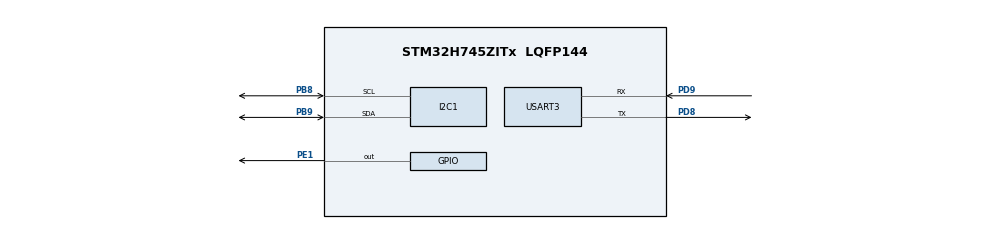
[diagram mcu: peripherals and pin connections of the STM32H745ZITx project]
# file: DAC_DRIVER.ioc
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CortexM4.IPs=FATFS_M4\:I,FREERTOS_M4\:I,IWDG2\:I,RCC,WWDG2\:I,DMA,BDMA,MDMA,NVIC2\:I,ETH,DEBUG,USB_DEVICE_M4\:I,USB_HOST_M4\:I,PDM2PCM_M4\:I,PWR,RESMGR_UTILITY,SYS_M4\:I,CORTEX_M4\:I,OPENAMP_M4\:I,VREFBUF,GPIO
CortexM7.IPs=FATFS_M7\:I,FREERTOS_M7\:I,IWDG1\:I,RCC\:I,WWDG1\:I,DMA\:I,BDMA\:I,MDMA\:I,NVIC1\:I,SYS\:I,ETH\:I,CORTEX_M7\:I,DEBUG\:I,USB_DEVICE_M7\:I,USB_HOST_M7\:I,PDM2PCM_M7\:I,PWR\:I,RESMGR_UTILITY\:I,OPENAMP_M7\:I,VREFBUF\:I,GPIO\:I,I2C1\:I,USART3\:I
CortexM7.Pins=PE1
I2C1.Analog_Filter=I2C_ANALOGFILTER_ENABLE
I2C1.Timing=0x00404C74
Mcu.Family=STM32H7
Mcu.Name=STM32H745ZITx
Mcu.Package=LQFP144
NVIC1.PriorityGroup=NVIC_PRIORITYGROUP_4
NVIC2.PriorityGroup=NVIC_PRIORITYGROUP_4
PB8.Mode=I2C
PB8.PinAttribute=CortexM7
PB8.Signal=I2C1_SCL
PB9.Mode=I2C
PB9.PinAttribute=CortexM7
PB9.Signal=I2C1_SDA
PD8.Mode=Asynchronous
PD8.PinAttribute=CortexM7
PD8.Signal=USART3_TX
PD9.Mode=Asynchronous
PD9.PinAttribute=CortexM7
PD9.Signal=USART3_RX
PE1.PinAttribute=CortexM7
PE1.Signal=GPIO_Output
ProjectManager.HeapSize=M4-0x200,M7-0x200
ProjectManager.StackSize=M4-0x400,M7-0x400
ProjectManager.TargetToolchain=STM32CubeIDE
RCC.ADCFreq_Value=129000000
RCC.APB1Freq_Value=20000000
RCC.APB2Freq_Value=20000000
RCC.APB3Freq_Value=20000000
RCC.APB4Freq_Value=20000000
RCC.CortexFreq_Value=80000000
RCC.D1PPRE=RCC_APB3_DIV2
RCC.D2PPRE1=RCC_APB1_DIV2
RCC.D2PPRE2=RCC_APB2_DIV2
RCC.D3PPRE=RCC_APB4_DIV2
RCC.DIVM1=4
RCC.DIVM3=1
RCC.DIVN1=10
RCC.DIVN3=24
RCC.DIVQ3=4
RCC.HCLKFreq_Value=40000000
RCC.HPRE=RCC_HCLK_DIV2
RCC.HSE_VALUE=8000000
RCC.PLL2FRACN=0
RCC.PLL3FRACN=0
RCC.PLLFRACN=0
RCC.SYSCLKFreq_VALUE=80000000
RCC.SYSCLKSource=RCC_SYSCLKSOURCE_PLLCLK
RCC.SupplySource=PWR_DIRECT_SMPS_SUPPLY
RCC.USBCLockSelection=RCC_USBCLKSOURCE_PLL3
RCC.USBFreq_Value=384000000
USART3.VirtualMode-Asynchronous=VM_ASYNC
VP_SYS_M4_VS_Systick.Mode=SysTick
board=NUCLEO-H745ZI-Q

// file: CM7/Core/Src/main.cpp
/* USER CODE BEGIN Header */
/**
  ******************************************************************************
  * @file           : main.c
  * @brief          : Main program body
  ******************************************************************************
  * @attention
  *
  * Copyright (c) 2022 STMicroelectronics.
  * All rights reserved.
  *
  * This software is licensed under terms that can be found in the LICENSE file
  * in the root directory of this software component.
  * If no LICENSE file comes with this software, it is provided AS-IS.
  *
  ******************************************************************************
  */
/* USER CODE END Header */
#include "main.h"

/* USER CODE BEGIN Includes */
#include <stdio.h>
#include "mcp4716_constants.hpp"  // Constants DAC IC
#include "bsp.hpp"
#include "IDriver.hpp"      // Parent Class
#include "Mcp4716Dac.hpp"  // Inherit class functions

/* USER CODE END Includes */

/* USER CODE BEGIN PD */

#ifndef HSEM_ID_0
#define HSEM_ID_0 (0U) /* HW semaphore 0*/
#endif
/* USER CODE END PD */

I2C_HandleTypeDef hi2c1;

UART_HandleTypeDef huart3;

void SystemClock_Config(void);
static void MX_GPIO_Init(void);
static void MX_I2C1_Init(void);
static void MX_USART3_UART_Init(void);

int main(void)
{
/* USER CODE BEGIN Boot_Mode_Sequence_0 */
  int32_t timeout;
/* USER CODE END Boot_Mode_Sequence_0 */

/* USER CODE BEGIN Boot_Mode_Sequence_1 */
  /* Wait until CPU2 boots and enters in stop mode or timeout*/
//  timeout = 0xFFFF;
//  while((__HAL_RCC_GET_FLAG(RCC_FLAG_D2CKRDY) != RESET) && (timeout-- > 0));
//  if ( timeout < 0 )
//  {
//  Error_Handler();
//  }
/* USER CODE END Boot_Mode_Sequence_1 */
  /* MCU Configuration--------------------------------------------------------*/

  /* Reset of all peripherals, Initializes the Flash interface and the Systick. */
  HAL_Init();

  /* Configure the system clock */
  SystemClock_Config();
/* USER CODE BEGIN Boot_Mode_Sequence_2 */
/* When system initialization is finished, Cortex-M7 will release Cortex-M4 by means of
HSEM notification */
/*HW semaphore Clock enable*/
__HAL_RCC_HSEM_CLK_ENABLE();
/*Take HSEM */
HAL_HSEM_FastTake(HSEM_ID_0);
/*Release HSEM in order to notify the CPU2(CM4)*/
HAL_HSEM_Release(HSEM_ID_0,0);
/* wait until CPU2 wakes up from stop mode */
timeout = 0xFFFF;
while((__HAL_RCC_GET_FLAG(RCC_FLAG_D2CKRDY) == RESET) && (timeout-- > 0));
if ( timeout < 0 )
{
Error_Handler();
}
/* USER CODE END Boot_Mode_Sequence_2 */

  /* Initialize all configured peripherals */
  MX_GPIO_Init();
  MX_I2C1_Init();
  MX_USART3_UART_Init();
  /* USER CODE BEGIN 2 */

  Mcp4716Dac mcp4716dac ;  //  Creating an Object
 //  ddriver -> toggleLed();
 //  mcp4716dac.Init();
 //  mcp4716dac.Write();
 //  mcp4716dac.Init();
 //    mcp4716dac.Write();
 //  mcp4716dac.Read();
 //  mcp4716dac.DeInit();
   //ddriver.DacVoltage(float vref,uint16_t dacvalue,float *voltage);

  /* USER CODE END 2 */

  /* Infinite loop */
  /* USER CODE BEGIN WHILE */
  while (1)
  {
      mcp4716dac.Init();
             mcp4716dac.Write();
             // mcp4716dac.Read();
              mcp4716dac.SerialData();

             mcp4716dac.toggleLed();

             mcp4716dac.GenerateVoltage(1020);

       //    HAL_GPIO_TogglePin(GPIOE,GPIO_PIN_1);
       //    HAL_Delay(500);
             HAL_GPIO_TogglePin(GPIOB,GPIO_PIN_0);
                 HAL_Delay(250);
    /* USER CODE END WHILE */

  }
}

void SystemClock_Config(void)
{
  RCC_OscInitTypeDef RCC_OscInitStruct = {0};
  RCC_ClkInitTypeDef RCC_ClkInitStruct = {0};

  /** Supply configuration update enable
  */
  HAL_PWREx_ConfigSupply(PWR_DIRECT_SMPS_SUPPLY);

  /** Configure the main internal regulator output voltage
  */
  __HAL_PWR_VOLTAGESCALING_CONFIG(PWR_REGULATOR_VOLTAGE_SCALE3);

  while(!__HAL_PWR_GET_FLAG(PWR_FLAG_VOSRDY)) {}

  /** Initializes the RCC Oscillators according to the specified parameters
  * in the RCC_OscInitTypeDef structure.
  */
  RCC_OscInitStruct.OscillatorType = RCC_OSCILLATORTYPE_HSI;
  RCC_OscInitStruct.HSIState = RCC_HSI_DIV1;
  RCC_OscInitStruct.HSICalibrationValue = RCC_HSICALIBRATION_DEFAULT;
  RCC_OscInitStruct.PLL.PLLState = RCC_PLL_ON;
  RCC_OscInitStruct.PLL.PLLSource = RCC_PLLSOURCE_HSI;
  RCC_OscInitStruct.PLL.PLLM = 4;
  RCC_OscInitStruct.PLL.PLLN = 10;
  RCC_OscInitStruct.PLL.PLLP = 2;
  RCC_OscInitStruct.PLL.PLLQ = 2;
  RCC_OscInitStruct.PLL.PLLR = 2;
  RCC_OscInitStruct.PLL.PLLRGE = RCC_PLL1VCIRANGE_3;
  RCC_OscInitStruct.PLL.PLLVCOSEL = RCC_PLL1VCOMEDIUM;
  RCC_OscInitStruct.PLL.PLLFRACN = 0;
  if (HAL_RCC_OscConfig(&RCC_OscInitStruct) != HAL_OK)
  {
    Error_Handler();
  }

  /** Initializes the CPU, AHB and APB buses clocks
  */
  RCC_ClkInitStruct.ClockType = RCC_CLOCKTYPE_HCLK|RCC_CLOCKTYPE_SYSCLK
                              |RCC_CLOCKTYPE_PCLK1|RCC_CLOCKTYPE_PCLK2
                              |RCC_CLOCKTYPE_D3PCLK1|RCC_CLOCKTYPE_D1PCLK1;
  RCC_ClkInitStruct.SYSCLKSource = RCC_SYSCLKSOURCE_PLLCLK;
  RCC_ClkInitStruct.SYSCLKDivider = RCC_SYSCLK_DIV1;
  RCC_ClkInitStruct.AHBCLKDivider = RCC_HCLK_DIV2;
  RCC_ClkInitStruct.APB3CLKDivider = RCC_APB3_DIV2;
  RCC_ClkInitStruct.APB1CLKDivider = RCC_APB1_DIV2;
  RCC_ClkInitStruct.APB2CLKDivider = RCC_APB2_DIV2;
  RCC_ClkInitStruct.APB4CLKDivider = RCC_APB4_DIV2;

  if (HAL_RCC_ClockConfig(&RCC_ClkInitStruct, FLASH_LATENCY_0) != HAL_OK)
  {
    Error_Handler();
  }
}

static void MX_I2C1_Init(void)
{

  hi2c1.Instance = I2C1;
  hi2c1.Init.Timing = 0x00404C74;
  hi2c1.Init.OwnAddress1 = 0;
  hi2c1.Init.AddressingMode = I2C_ADDRESSINGMODE_7BIT;
  hi2c1.Init.DualAddressMode = I2C_DUALADDRESS_DISABLE;
  hi2c1.Init.OwnAddress2 = 0;
  hi2c1.Init.OwnAddress2Masks = I2C_OA2_NOMASK;
  hi2c1.Init.GeneralCallMode = I2C_GENERALCALL_DISABLE;
  hi2c1.Init.NoStretchMode = I2C_NOSTRETCH_DISABLE;
  if (HAL_I2C_Init(&hi2c1) != HAL_OK)
  {
    Error_Handler();
  }

  /** Configure Analogue filter
  */
  if (HAL_I2CEx_ConfigAnalogFilter(&hi2c1, I2C_ANALOGFILTER_ENABLE) != HAL_OK)
  {
    Error_Handler();
  }

  /** Configure Digital filter
  */
  if (HAL_I2CEx_ConfigDigitalFilter(&hi2c1, 0) != HAL_OK)
  {
    Error_Handler();
  }

}

static void MX_USART3_UART_Init(void)
{

  huart3.Instance = USART3;
  huart3.Init.BaudRate = 115200;
  huart3.Init.WordLength = UART_WORDLENGTH_8B;
  huart3.Init.StopBits = UART_STOPBITS_1;
  huart3.Init.Parity = UART_PARITY_NONE;
  huart3.Init.Mode = UART_MODE_TX_RX;
  huart3.Init.HwFlowCtl = UART_HWCONTROL_NONE;
  huart3.Init.OverSampling = UART_OVERSAMPLING_16;
  huart3.Init.OneBitSampling = UART_ONE_BIT_SAMPLE_DISABLE;
  huart3.Init.ClockPrescaler = UART_PRESCALER_DIV1;
  huart3.AdvancedInit.AdvFeatureInit = UART_ADVFEATURE_NO_INIT;
  if (HAL_UART_Init(&huart3) != HAL_OK)
  {
    Error_Handler();
  }
  if (HAL_UARTEx_SetTxFifoThreshold(&huart3, UART_TXFIFO_THRESHOLD_1_8) != HAL_OK)
  {
    Error_Handler();
  }
  if (HAL_UARTEx_SetRxFifoThreshold(&huart3, UART_RXFIFO_THRESHOLD_1_8) != HAL_OK)
  {
    Error_Handler();
  }
  if (HAL_UARTEx_DisableFifoMode(&huart3) != HAL_OK)
  {
    Error_Handler();
  }

}

static void MX_GPIO_Init(void)
{
  GPIO_InitTypeDef GPIO_InitStruct = {0};

  /* GPIO Ports Clock Enable */
  __HAL_RCC_GPIOD_CLK_ENABLE();
  __HAL_RCC_GPIOB_CLK_ENABLE();
  __HAL_RCC_GPIOE_CLK_ENABLE();

  /*Configure GPIO pin Output Level */
  HAL_GPIO_WritePin(GPIOE, GPIO_PIN_1, GPIO_PIN_RESET);

  /*Configure GPIO pin : PE1 */
  GPIO_InitStruct.Pin = GPIO_PIN_1;
  GPIO_InitStruct.Mode = GPIO_MODE_OUTPUT_PP;
  GPIO_InitStruct.Pull = GPIO_NOPULL;
  GPIO_InitStruct.Speed = GPIO_SPEED_FREQ_LOW;
  HAL_GPIO_Init(GPIOE, &GPIO_InitStruct);

}

void Error_Handler(void)
{
  __disable_irq();
  while (1)
  {
  }
}
